# ATSAML21E18A device description
Architecture: CORTEX-M0PLUS; Family: SAML; Series: SAML21
Registers are 32-bit, read-write, reset 0x0 unless marked. A register's access mark holds for its fields unless they carry their own. Offsets are from the block's base; [hi:lo] are bit positions; {n}, {i} and the like mark numbered series; 'fields as' and 'values as' point back to an identical list.

## OTP5_FUSES — Non-Volatile Fuses
Instances: OTP5_FUSES 0x00806020 in fuses
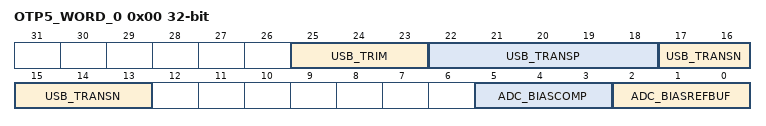
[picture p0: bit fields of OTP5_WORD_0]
0x00 OTP5_WORD_0 ro reset not defined — OTP5 Page Word 0
  [25:23] USB_TRIM — USB pad Trim calibration
  [22:18] USB_TRANSP — USB pad Transp calibration
  [17:13] USB_TRANSN — USB pad Transn calibration
  [5:3] ADC_BIASCOMP — ADC Comparator Scaling
  [2:0] ADC_BIASREFBUF — ADC Bias Reference Buffer Scaling

## TEMP_LOG_FUSES — Non-Volatile Fuses
Instances: TEMP_LOG_FUSES 0x00806030 in fuses
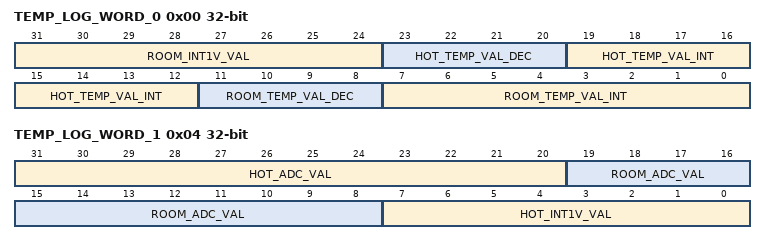
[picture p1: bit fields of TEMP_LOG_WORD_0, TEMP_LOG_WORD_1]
0x00 TEMP_LOG_WORD_0 ro reset not defined — TEMP_LOG Page Word 0
  [31:24] ROOM_INT1V_VAL — 2's complement of the internal 1V reference drift at room temperature (versus a 1.0 centered value)
  [23:20] HOT_TEMP_VAL_DEC — Decimal part of hot temperature
  [19:12] HOT_TEMP_VAL_INT — Integer part of hot temperature in oC
  [11:8] ROOM_TEMP_VAL_DEC — Decimal part of room temperature
  [7:0] ROOM_TEMP_VAL_INT — Integer part of room temperature in oC
0x04 TEMP_LOG_WORD_1 ro reset not defined — TEMP_LOG Page Word 1
  [31:20] HOT_ADC_VAL — 12-bit ADC conversion at hot temperature
  [19:8] ROOM_ADC_VAL — 12-bit ADC conversion at room temperature
  [7:0] HOT_INT1V_VAL — 2's complement of the internal 1V reference drift at hot temperature (versus a 1.0 centered value)

## USER_FUSES — Non-Volatile Fuses
Instances: USER_FUSES 0x00804000 in fuses
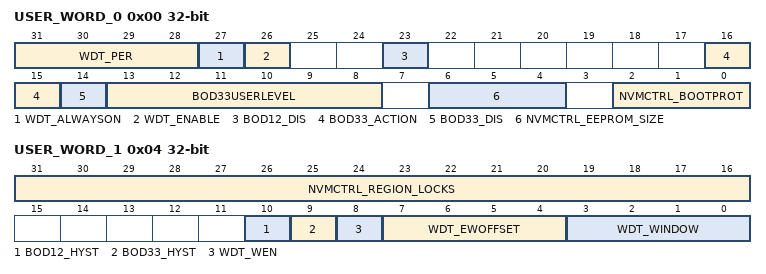
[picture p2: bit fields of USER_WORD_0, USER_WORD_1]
0x00 USER_WORD_0 reset not defined — USER Page Word 0
  [31:28] WDT_PER — WDT Period
  [27] WDT_ALWAYSON
  [26] WDT_ENABLE
  [23] BOD12_DIS — BOD12 Disable
  [16:15] BOD33_ACTION
  [14] BOD33_DIS — BOD33 Disable
  [13:8] BOD33USERLEVEL
  [6:4] NVMCTRL_EEPROM_SIZE — EEPROM Size
  [2:0] NVMCTRL_BOOTPROT — Bootloader Size
0x04 USER_WORD_1 reset not defined — USER Page Word 1
  [31:16] NVMCTRL_REGION_LOCKS — NVM Region Locks
  [10] BOD12_HYST — BOD12 Hysteresis
  [9] BOD33_HYST — BOD33 Hysteresis
  [8] WDT_WEN — WDT Window Mode Enable
  [7:4] WDT_EWOFFSET — WDT Early Warning Offset
  [3:0] WDT_WINDOW

## OPAMP — Operational Amplifier
Instances: OPAMP 0x43001800
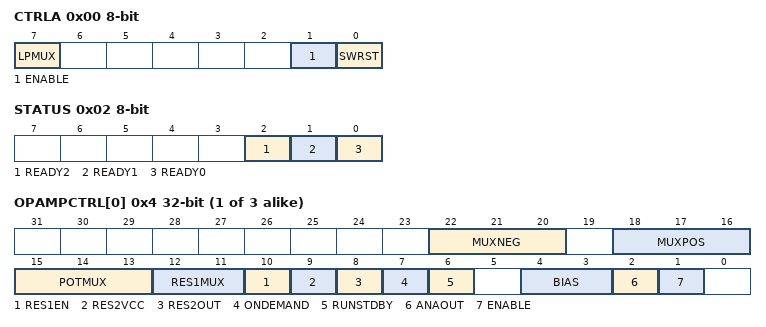
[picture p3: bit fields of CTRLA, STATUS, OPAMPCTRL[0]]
0x00 CTRLA 8-bit — Control A
  [7] LPMUX — Low-Power Mux
  [1] ENABLE
  [0] SWRST — Software Reset
0x02 STATUS 8-bit ro
  [2] READY2 — OPAMP 2 Ready
  [1] READY1 — OPAMP 1 Ready
  [0] READY0 — OPAMP 0 Ready
{0x4+4i} OPAMPCTRL[{i}] (i=0..2) — OPAMP Control n
  [22:20] MUXNEG — Negative Input Mux Selection
  [18:16] MUXPOS — Positive Input Mux Selection
  [15:13] POTMUX — Potentiometer Selection
  [12:11] RES1MUX — Resistor 1 Mux
  [10] RES1EN — Resistor 1 Enable
  [9] RES2VCC — Resistor ladder To VCC
  [8] RES2OUT — Resistor ladder To Output
  [7] ONDEMAND — On Demand Control
  [6] RUNSTDBY — Run in Standby
  [4:3] BIAS — Bias Selection
  [2] ANAOUT — Analog Output
  [1] ENABLE — Operational Amplifier Enable

## OSC32KCTRL — 32k Oscillators Control
Instances: OSC32KCTRL 0x40001000
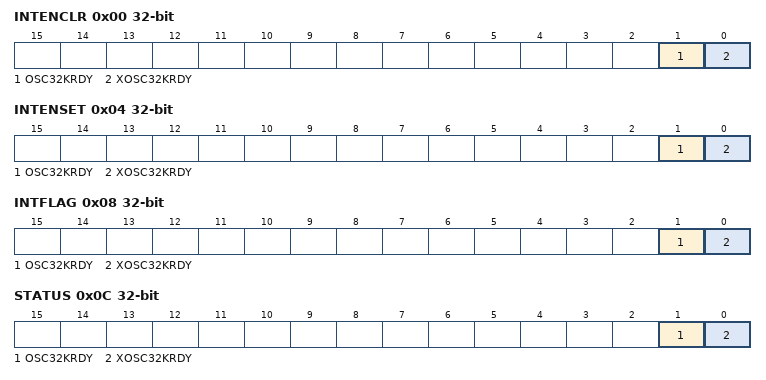
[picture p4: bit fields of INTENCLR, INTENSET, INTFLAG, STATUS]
0x00 INTENCLR (atomic clear) — Interrupt Enable Clear
  [1] OSC32KRDY — OSC32K Ready Interrupt Enable
  [0] XOSC32KRDY — XOSC32K Ready Interrupt Enable
0x04 INTENSET (atomic set) — Interrupt Enable Set
  fields as INTENCLR
0x08 INTFLAG (atomic clear) — Interrupt Flag Status and Clear
  [1] OSC32KRDY — OSC32K Ready
  [0] XOSC32KRDY — XOSC32K Ready
0x0C STATUS ro — Power and Clocks Status
  [1] OSC32KRDY — OSC32K Ready
  [0] XOSC32KRDY — XOSC32K Ready
0x10 RTCCTRL — Clock selection
  [2:0] RTCSEL — RTC Clock Selection
    0=ULP1K (1.024kHz from 32kHz internal ULP oscillator); 1=ULP32K (32.768kHz from 32kHz internal ULP oscillator); 2=OSC1K (1.024kHz from 32.768kHz internal oscillator); 3=OSC32K (32.768kHz from 32.768kHz internal oscillator); 4=XOSC1K (1.024kHz from 32.768kHz internal oscillator); 5=XOSC32K (32.768kHz from 32.768kHz external crystal oscillator)
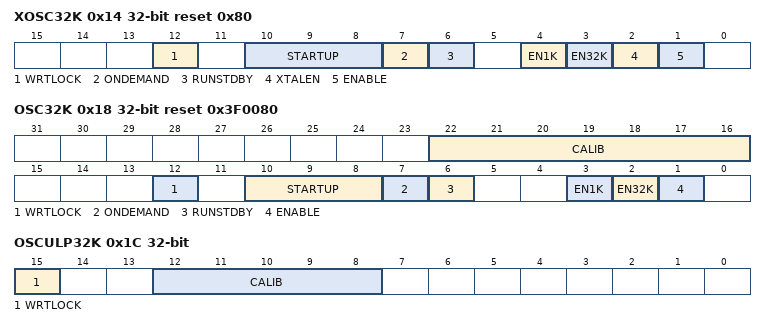
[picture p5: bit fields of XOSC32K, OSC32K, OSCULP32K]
0x14 XOSC32K reset 0x80 — 32kHz External Crystal Oscillator (XOSC32K) Control
  [12] WRTLOCK — Write Lock
  [10:8] STARTUP — Oscillator Start-Up Time
  [7] ONDEMAND — On Demand Control
  [6] RUNSTDBY — Run in Standby
  [4] EN1K — 1kHz Output Enable
  [3] EN32K — 32kHz Output Enable
  [2] XTALEN — Crystal Oscillator Enable
  [1] ENABLE — Oscillator Enable
0x18 OSC32K reset 0x3F0080 — 32kHz Internal Oscillator (OSC32K) Control
  [22:16] CALIB — Oscillator Calibration
  [12] WRTLOCK — Write Lock
  [10:8] STARTUP — Oscillator Start-Up Time
  [7] ONDEMAND — On Demand Control
  [6] RUNSTDBY — Run in Standby
  [3] EN1K — 1kHz Output Enable
  [2] EN32K — 32kHz Output Enable
  [1] ENABLE — Oscillator Enable
0x1C OSCULP32K reset not defined — 32kHz Ultra Low Power Internal Oscillator (OSCULP32K) Control
  [15] WRTLOCK — Write Lock
  [12:8] CALIB — Oscillator Calibration

## Notices in the file
Copyright (c) 2018 Microchip Technology Inc.
SPDX-License-Identifier: Apache-2.0
Licensed under the Apache License, Version 2.0 (the "License");
you may not use this file except in compliance with the License.
You may obtain a copy of the License at
http://www.apache.org/licenses/LICENSE-2.0
Unless required by applicable law or agreed to in writing, software
distributed under the License is distributed on an "AS IS" BASIS,
WITHOUT WARRANTIES OR CONDITIONS OF ANY KIND, either express or implied.
See the License for the specific language governing permissions and
limitations under the License.
